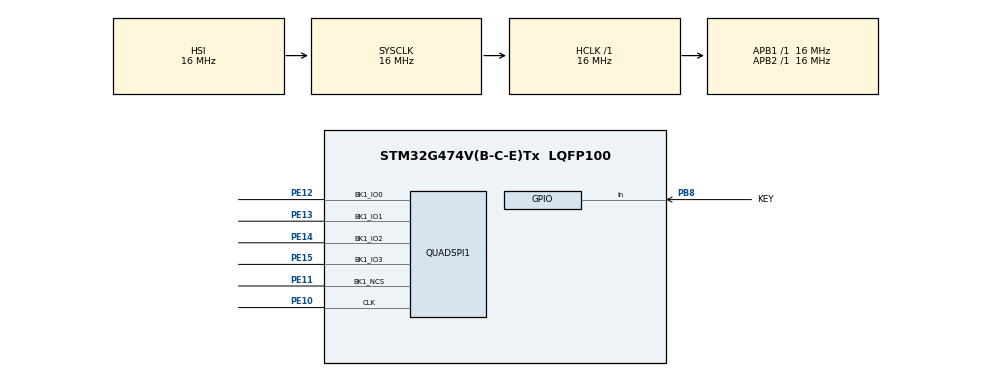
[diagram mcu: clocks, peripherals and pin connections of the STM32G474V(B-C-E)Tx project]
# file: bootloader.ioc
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IWDG.Prescaler=IWDG_PRESCALER_256
IWDG.Reload=4095
IWDG.Window=4095
Mcu.Family=STM32G4
Mcu.Name=STM32G474V(B-C-E)Tx
Mcu.Package=LQFP100
NVIC.PriorityGroup=NVIC_PRIORITYGROUP_4
NVIC.QUADSPI_IRQn=true\:5\:0\:false\:false\:true\:true\:true\:true
PA13.Mode=Serial_Wire
PA13.Signal=SYS_JTMS-SWDIO
PA14.Mode=Serial_Wire
PA14.Signal=SYS_JTCK-SWCLK
PB8-BOOT0.GPIO_Label=KEY
PB8-BOOT0.Signal=GPIO_Input
PE10.GPIO_PuPd=GPIO_NOPULL
PE10.GPIO_Speed=GPIO_SPEED_FREQ_VERY_HIGH
PE10.Mode=Single Bank 1
PE10.Signal=QUADSPI1_CLK
PE11.GPIO_PuPd=GPIO_NOPULL
PE11.GPIO_Speed=GPIO_SPEED_FREQ_VERY_HIGH
PE11.Mode=Single Bank 1
PE11.Signal=QUADSPI1_BK1_NCS
PE12.GPIO_PuPd=GPIO_NOPULL
PE12.GPIO_Speed=GPIO_SPEED_FREQ_VERY_HIGH
PE12.Mode=Single Bank 1
PE12.Signal=QUADSPI1_BK1_IO0
PE13.GPIO_PuPd=GPIO_NOPULL
PE13.GPIO_Speed=GPIO_SPEED_FREQ_VERY_HIGH
PE13.Mode=Single Bank 1
PE13.Signal=QUADSPI1_BK1_IO1
PE14.GPIO_PuPd=GPIO_NOPULL
PE14.GPIO_Speed=GPIO_SPEED_FREQ_VERY_HIGH
PE14.Mode=Single Bank 1
PE14.Signal=QUADSPI1_BK1_IO2
PE15.GPIO_PuPd=GPIO_NOPULL
PE15.GPIO_Speed=GPIO_SPEED_FREQ_VERY_HIGH
PE15.Mode=Single Bank 1
PE15.Signal=QUADSPI1_BK1_IO3
ProjectManager.HeapSize=0x200
ProjectManager.StackSize=0x400
ProjectManager.TargetToolchain=STM32CubeIDE
QUADSPI1.ChipSelectHighTime=QSPI_CS_HIGH_TIME_3_CYCLE
QUADSPI1.ClockMode=QSPI_CLOCK_MODE_0
QUADSPI1.ClockPrescaler=1
QUADSPI1.DualFlash=QSPI_DUALFLASH_DISABLE
QUADSPI1.FifoThreshold=4
QUADSPI1.FlashID=QSPI_FLASH_ID_1
QUADSPI1.FlashSize=22
QUADSPI1.SampleShifting=QSPI_SAMPLE_SHIFTING_NONE
RCC.ADC12Freq_Value=16000000
RCC.ADC345Freq_Value=16000000
RCC.AHBFreq_Value=16000000
RCC.APB1Freq_Value=16000000
RCC.APB1TimFreq_Value=16000000
RCC.APB2Freq_Value=16000000
RCC.APB2TimFreq_Value=16000000
RCC.CortexFreq_Value=16000000
RCC.EXTERNAL_CLOCK_VALUE=12288000
RCC.HCLKFreq_Value=16000000
RCC.HSE_VALUE=8000000
RCC.HSI48_VALUE=48000000
RCC.HSI_VALUE=16000000
RCC.LSE_VALUE=32768
RCC.SYSCLKFreq_VALUE=16000000
RCC.SYSCLKSource=RCC_SYSCLKSOURCE_HSI
RCC.USBFreq_Value=16000000
VP_IWDG_VS_IWDG.Mode=IWDG_Activate
VP_SYS_VS_DBSignals.Mode=DisableDeadBatterySignals
board=custom

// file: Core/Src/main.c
/* USER CODE BEGIN Header */
/**
  ******************************************************************************
  * @file           : main.c
  * @brief          : Main program body
  ******************************************************************************
  * @attention
  *
  * Copyright (c) 2026 STMicroelectronics.
  * All rights reserved.
  *
  * This software is licensed under terms that can be found in the LICENSE file
  * in the root directory of this software component.
  * If no LICENSE file comes with this software, it is provided AS-IS.
  *
  ******************************************************************************
  */
/* USER CODE END Header */
#include "main.h"
#include "iwdg.h"
#include "quadspi.h"
#include "gpio.h"

/* USER CODE BEGIN Includes */

#include "boot/boot_main.h"

/* USER CODE END Includes */

void SystemClock_Config(void);

int main(void)
{

  /* USER CODE BEGIN 1 */

  SCB->VTOR = FLASH_BASE;
  __DSB();
  __ISB();

  /* An IWDG started before a software reset remains active. */
  BootWatchdog_Refresh();

  /* USER CODE END 1 */

  /* MCU Configuration--------------------------------------------------------*/

  /* Reset of all peripherals, Initializes the Flash interface and the Systick. */
  HAL_Init();

  /* Configure the system clock */
  SystemClock_Config();

  /* Initialize all configured peripherals */
  MX_GPIO_Init();
  MX_QUADSPI1_Init();
  MX_IWDG_Init();
  /* USER CODE BEGIN 2 */

  BootWatchdog_Refresh();
  BootMain_Run();

  /* USER CODE END 2 */

  /* Infinite loop */
  while (1)
  {

  }
}

void SystemClock_Config(void)
{
  RCC_OscInitTypeDef RCC_OscInitStruct = {0};
  RCC_ClkInitTypeDef RCC_ClkInitStruct = {0};

  /** Configure the main internal regulator output voltage
  */
  HAL_PWREx_ControlVoltageScaling(PWR_REGULATOR_VOLTAGE_SCALE1);

  /** Initializes the RCC Oscillators according to the specified parameters
  * in the RCC_OscInitTypeDef structure.
  */
  RCC_OscInitStruct.OscillatorType = RCC_OSCILLATORTYPE_HSI|RCC_OSCILLATORTYPE_LSI;
  RCC_OscInitStruct.HSIState = RCC_HSI_ON;
  RCC_OscInitStruct.HSICalibrationValue = RCC_HSICALIBRATION_DEFAULT;
  RCC_OscInitStruct.LSIState = RCC_LSI_ON;
  RCC_OscInitStruct.PLL.PLLState = RCC_PLL_NONE;
  if (HAL_RCC_OscConfig(&RCC_OscInitStruct) != HAL_OK)
  {
    Error_Handler();
  }

  /** Initializes the CPU, AHB and APB buses clocks
  */
  RCC_ClkInitStruct.ClockType = RCC_CLOCKTYPE_HCLK|RCC_CLOCKTYPE_SYSCLK
                              |RCC_CLOCKTYPE_PCLK1|RCC_CLOCKTYPE_PCLK2;
  RCC_ClkInitStruct.SYSCLKSource = RCC_SYSCLKSOURCE_HSI;
  RCC_ClkInitStruct.AHBCLKDivider = RCC_SYSCLK_DIV1;
  RCC_ClkInitStruct.APB1CLKDivider = RCC_HCLK_DIV1;
  RCC_ClkInitStruct.APB2CLKDivider = RCC_HCLK_DIV1;

  if (HAL_RCC_ClockConfig(&RCC_ClkInitStruct, FLASH_LATENCY_0) != HAL_OK)
  {
    Error_Handler();
  }
}

void Error_Handler(void)
{
  __disable_irq();
  while (1)
  {
  }
}
